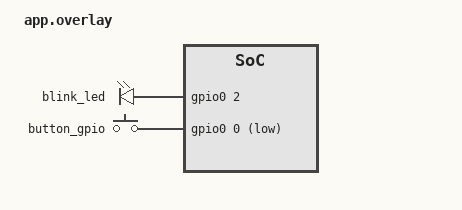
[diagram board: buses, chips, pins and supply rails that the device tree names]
/ {
    aliases {
        led0 = &blink_led;
        button0 = &button_gpio;
    };

    leds {
        compatible = "gpio-leds";
        blink_led: led_gpio {
            gpios = <&gpio0 2 GPIO_ACTIVE_HIGH>;
        };
    };

    buttons {
        compatible = "gpio-keys";
        button_gpio: button_gpio {
            gpios = <&gpio0 0 (GPIO_PULL_UP | GPIO_ACTIVE_LOW)>;
        };
    };
};
